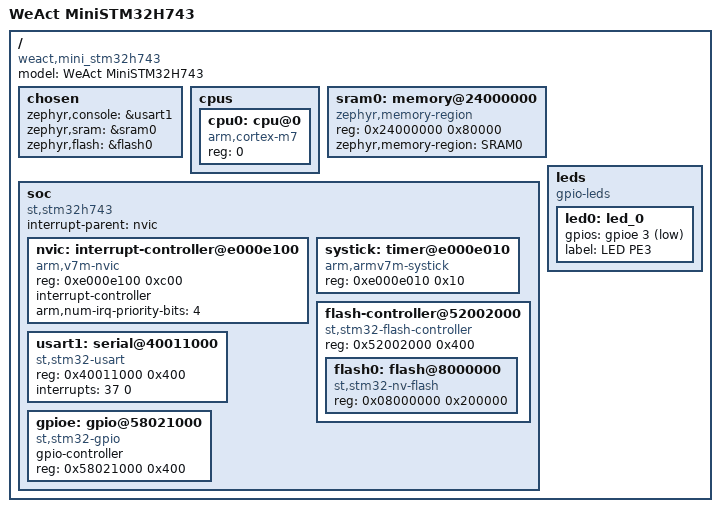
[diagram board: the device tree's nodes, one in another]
/*
 * weact_h743.dts: a small, already-flattened Zephyr-style devicetree for the WeAct
 * MiniSTM32H743 core board (STM32H743VIT6, LED PE3, USART1 PA9/PA10). In a real project
 * use the zephyr.dts that a Zephyr build writes to build/zephyr/zephyr.dts.
 * ./renode-box repl weact_h743.dts -o weact_h743.repl   (dts2repl)
 */
/dts-v1/;

/ {
	#address-cells = <1>;
	#size-cells = <1>;
	model = "WeAct MiniSTM32H743";
	compatible = "weact,mini_stm32h743", "st,stm32h743";

	chosen {
		zephyr,console = &usart1;
		zephyr,sram = &sram0;
		zephyr,flash = &flash0;
	};

	cpus {
		#address-cells = <1>;
		#size-cells = <0>;
		cpu0: cpu@0 {
			device_type = "cpu";
			compatible = "arm,cortex-m7";
			reg = <0>;
		};
	};

	sram0: memory@24000000 {
		compatible = "zephyr,memory-region", "mmio-sram";
		reg = <0x24000000 0x80000>;
		zephyr,memory-region = "SRAM0";
	};

	soc {
		#address-cells = <1>;
		#size-cells = <1>;
		compatible = "st,stm32h743", "st,stm32h7", "simple-bus";
		interrupt-parent = <&nvic>;
		ranges;

		nvic: interrupt-controller@e000e100 {
			#address-cells = <1>;
			compatible = "arm,v7m-nvic";
			reg = <0xe000e100 0xc00>;
			interrupt-controller;
			#interrupt-cells = <2>;
			arm,num-irq-priority-bits = <4>;
		};

		systick: timer@e000e010 {
			compatible = "arm,armv7m-systick";
			reg = <0xe000e010 0x10>;
		};

		flash-controller@52002000 {
			compatible = "st,stm32-flash-controller", "st,stm32h7-flash-controller";
			reg = <0x52002000 0x400>;
			#address-cells = <1>;
			#size-cells = <1>;
			flash0: flash@8000000 {
				compatible = "st,stm32-nv-flash", "soc-nv-flash";
				reg = <0x08000000 0x200000>;
			};
		};

		usart1: serial@40011000 {
			compatible = "st,stm32-usart", "st,stm32-uart";
			reg = <0x40011000 0x400>;
			interrupts = <37 0>;
			status = "okay";
		};

		gpioe: gpio@58021000 {
			compatible = "st,stm32-gpio";
			gpio-controller;
			#gpio-cells = <2>;
			reg = <0x58021000 0x400>;
		};
	};

	leds {
		compatible = "gpio-leds";
		led0: led_0 {
			gpios = <&gpioe 3 1>;
			label = "LED PE3";
		};
	};
};
